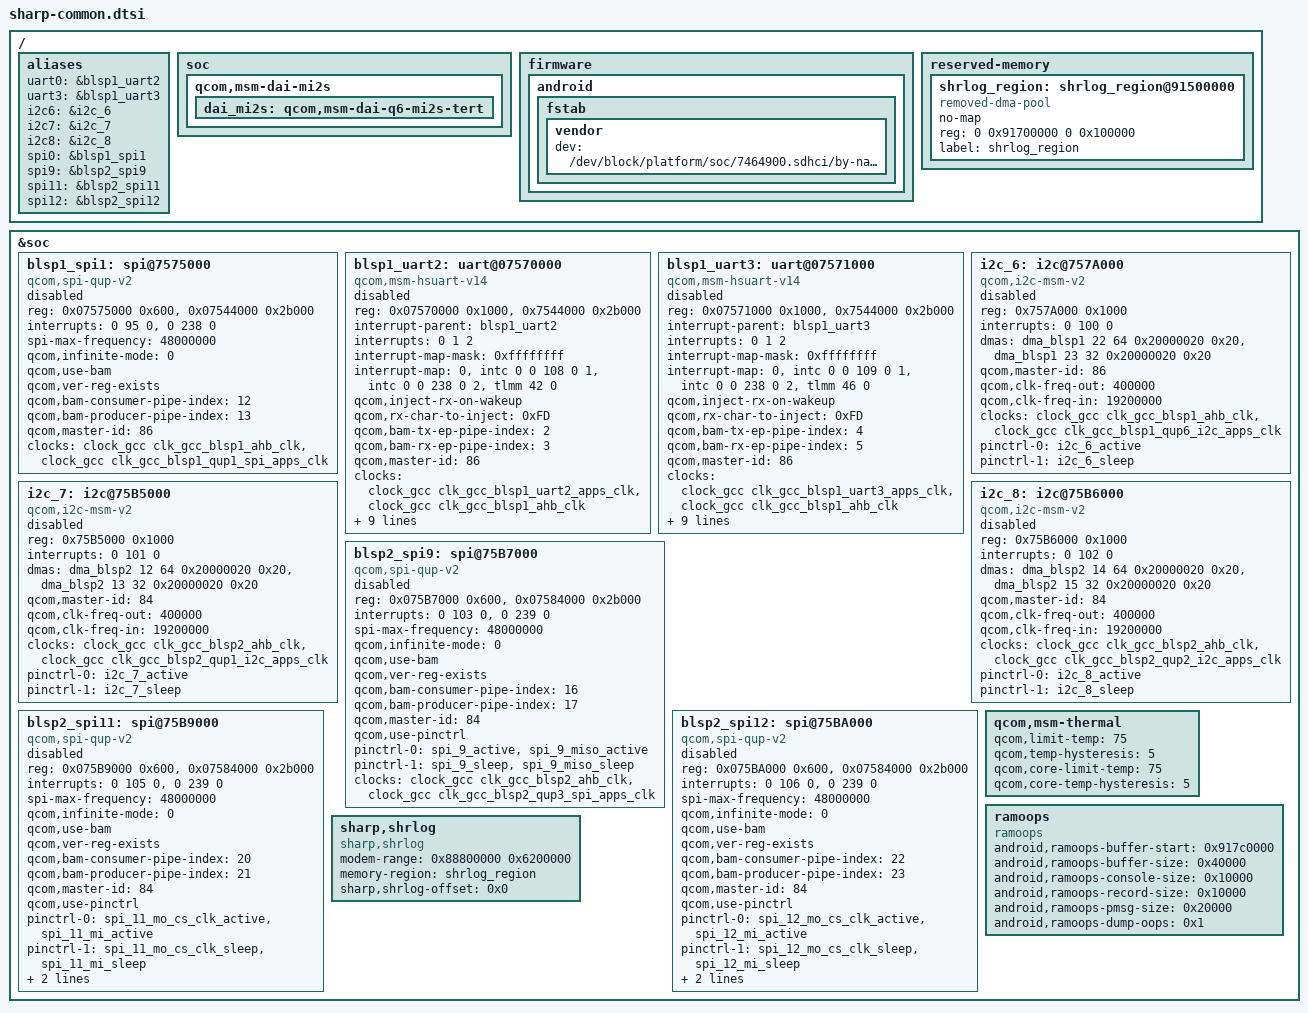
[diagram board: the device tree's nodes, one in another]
/* Copyright (c) 2015, The Linux Foundation. All rights reserved.
 *
 * This program is free software; you can redistribute it and/or modify
 * it under the terms of the GNU General Public License version 2 and
 * only version 2 as published by the Free Software Foundation.
 *
 * This program is distributed in the hope that it will be useful,
 * but WITHOUT ANY WARRANTY; without even the implied warranty of
 * MERCHANTABILITY or FITNESS FOR A PARTICULAR PURPOSE.  See the
 * GNU General Public License for more details.
 */

/*****************************************/
/*  Add SHARP include                    */
/*****************************************/
#include "sharp-pinctrl.dtsi"
#include "sharp-common-pm8996.dtsi"
#include "sharp-common-pmi8994.dtsi"
#include "sharp-common-sdcc.dtsi"

/*----------------------------------------*/
/* Qualcomm settings.                     */
/*----------------------------------------*/
/ {
	aliases {
		uart0 = &blsp1_uart2;
		uart3 = &blsp1_uart3;

		i2c6 = &i2c_6;
		i2c7 = &i2c_7;
		i2c8 = &i2c_8;

		spi0 = &blsp1_spi1;
		spi9 = &blsp2_spi9;
		spi11 = &blsp2_spi11;
		spi12 = &blsp2_spi12;
	};

	soc {
		/delete-node/ i2c@75b5000;
		/delete-node/ i2c@75b6000;
		/delete-node/ i2c@75ba000;
		/delete-node/ spi@7575000;
		/delete-node/ uart@07570000;
		/delete-node/ serial@07570000;
		/delete-node/ serial@075b0000;

		qcom,msm-dai-mi2s {
			dai_mi2s: qcom,msm-dai-q6-mi2s-tert {
				/delete-property/ pinctrl-names;
				/delete-property/ pinctrl-0;
				/delete-property/ pinctrl-1;
			};
		};
	};

	firmware: firmware {
		android {
			fstab {
				vendor {
					dev = "/dev/block/platform/soc/7464900.sdhci/by-name/systemex";
				 };
			};
		};
	};

	/*----------------------------------------------*/
	/* shrlog                                       */
	/*----------------------------------------------*/
	reserved-memory {
		shrlog_region: shrlog_region@91500000 {
			compatible = "removed-dma-pool";
			no-map;
			reg = <0 0x91700000 0 0x100000>;
			label = "shrlog_region";
		};
	};
};

/*----------------------------------------*/
/* Add SHARP settings.                    */
/*----------------------------------------*/
&soc {
	/*---------------------*/
	/* BLSP1 QUP0(BLSP#1)  */
	/*---------------------*/
	blsp1_spi1: spi@7575000 {
		compatible = "qcom,spi-qup-v2";
		#address-cells = <1>;
		#size-cells = <0>;
		reg-names = "spi_physical", "spi_bam_physical";
		reg = <0x07575000 0x600>,
		      <0x07544000 0x2b000>;
		interrupt-names = "spi_irq", "spi_bam_irq";
		interrupts = <0 95 0>, <0 238 0>;
		spi-max-frequency = <48000000>;

		qcom,infinite-mode = <0>;
		qcom,use-bam;
		qcom,ver-reg-exists;
		qcom,bam-consumer-pipe-index = <12>;
		qcom,bam-producer-pipe-index = <13>;
		qcom,master-id = <86>;

		clock-names = "iface_clk", "core_clk";
		clocks = <&clock_gcc clk_gcc_blsp1_ahb_clk>,
			 <&clock_gcc clk_gcc_blsp1_qup1_spi_apps_clk>;
		status = "disabled";
	};

	/*---------------------*/
	/* BLSP1 UART1(BLSP#2) */
	/*---------------------*/
	blsp1_uart2: uart@07570000 {
		compatible = "qcom,msm-hsuart-v14";
		reg = <0x07570000 0x1000>,
		    <0x7544000 0x2b000>;
		reg-names = "core_mem", "bam_mem";
		interrupt-names = "core_irq", "bam_irq", "wakeup_irq";
		#address-cells = <0>;
		interrupt-parent = <&blsp1_uart2>;
		interrupts = <0 1 2>;
		#interrupt-cells = <1>;
		interrupt-map-mask = <0xffffffff>;
		interrupt-map = <0 &intc 0 0 108 0
			    1 &intc 0 0 238 0
			    2 &tlmm 42 0>;

		qcom,inject-rx-on-wakeup;
		qcom,rx-char-to-inject = <0xFD>;

		qcom,bam-tx-ep-pipe-index = <2>;
		qcom,bam-rx-ep-pipe-index = <3>;
		qcom,master-id = <86>;
		clock-names = "core_clk", "iface_clk";
		clocks = <&clock_gcc clk_gcc_blsp1_uart2_apps_clk>,
		    <&clock_gcc clk_gcc_blsp1_ahb_clk>;
		pinctrl-names = "sleep", "default";
// Bluetooth Driver Mod-S
//		pinctrl-0 = <&blsp1_uart2_sleep>;
//		pinctrl-1 = <&blsp1_uart2_active>;
		pinctrl-0 = <&blsp1_uart2_sleep &blsp1_uart2_rts_sleep>;
		pinctrl-1 = <&blsp1_uart2_active &blsp1_uart2_rts_active>;
// Bluetooth Driver Mod-E

		qcom,msm-bus,name = "buart2";
		qcom,msm-bus,num-cases = <2>;
		qcom,msm-bus,num-paths = <1>;
		qcom,msm-bus,vectors-KBps =
			    <86 512 0 0>,
			    <86 512 500 800>;
		status = "disabled";
	};

	/*---------------------*/
	/* BLSP1 UART2(BLSP#3) */
	/*---------------------*/
	blsp1_uart3: uart@07571000 {
		compatible = "qcom,msm-hsuart-v14";
		reg = <0x07571000 0x1000>,
		    <0x7544000 0x2b000>;
		reg-names = "core_mem", "bam_mem";
		interrupt-names = "core_irq", "bam_irq", "wakeup_irq";
		#address-cells = <0>;
		interrupt-parent = <&blsp1_uart3>;
		interrupts = <0 1 2>;
		#interrupt-cells = <1>;
		interrupt-map-mask = <0xffffffff>;
		interrupt-map = <0 &intc 0 0 109 0
			    1 &intc 0 0 238 0
			    2 &tlmm 46 0>;

		qcom,inject-rx-on-wakeup;
		qcom,rx-char-to-inject = <0xFD>;

		qcom,bam-tx-ep-pipe-index = <4>;
		qcom,bam-rx-ep-pipe-index = <5>;
		qcom,master-id = <86>;
		clock-names = "core_clk", "iface_clk";
		clocks = <&clock_gcc clk_gcc_blsp1_uart3_apps_clk>,
		    <&clock_gcc clk_gcc_blsp1_ahb_clk>;
		pinctrl-names = "sleep", "default";
		pinctrl-0 = <&blsp1_uart3_sleep_tx_rx &blsp1_uart3_sleep_cts_ref>;
		pinctrl-1 = <&blsp1_uart3_active_tx_rx &blsp1_uart3_active_cts_ref>;

		qcom,msm-bus,name = "buart3";
		qcom,msm-bus,num-cases = <2>;
		qcom,msm-bus,num-paths = <1>;
		qcom,msm-bus,vectors-KBps =
			    <86 512 0 0>,
			    <86 512 500 800>;
		status = "disabled";
	};

	/*---------------------*/
	/* BLSP#4              */
	/*---------------------*/

	/*---------------------*/
	/* BLSP#5              */
	/*---------------------*/

	/*---------------------*/
	/* BLSP1 QUP5(BLSP#6)  */
	/*---------------------*/
	i2c_6: i2c@757A000 {
		compatible = "qcom,i2c-msm-v2";
		#address-cells = <1>;
		#size-cells = <0>;
		reg-names = "qup_phys_addr";
		reg = <0x757A000 0x1000>;
		interrupt-names = "qup_irq";
		interrupts = <0 100 0>;
		dmas = <&dma_blsp1 22 64 0x20000020 0x20>,
			<&dma_blsp1 23 32 0x20000020 0x20>;
		dma-names = "tx", "rx";
		qcom,master-id = <86>;
		qcom,clk-freq-out = <400000>;
		qcom,clk-freq-in  = <19200000>;
		clock-names = "iface_clk", "core_clk";
		clocks = <&clock_gcc clk_gcc_blsp1_ahb_clk>,
			 <&clock_gcc clk_gcc_blsp1_qup6_i2c_apps_clk>;
		pinctrl-names = "i2c_active", "i2c_sleep";
		pinctrl-0 = <&i2c_6_active>;
		pinctrl-1 = <&i2c_6_sleep>;
		status = "disabled";
	};

	/*---------------------*/
	/* BLSP2 QUP0(BLSP#7)  */
	/*---------------------*/
	i2c_7: i2c@75B5000 {
		compatible = "qcom,i2c-msm-v2";
		#address-cells = <1>;
		#size-cells = <0>;
		reg-names = "qup_phys_addr";
		reg = <0x75B5000 0x1000>;
		interrupt-names = "qup_irq";
		interrupts = <0 101 0>;
		dmas = <&dma_blsp2 12 64 0x20000020 0x20>,
			<&dma_blsp2 13 32 0x20000020 0x20>;
		dma-names = "tx", "rx";
		qcom,master-id = <84>;
		qcom,clk-freq-out = <400000>;
		qcom,clk-freq-in  = <19200000>;
		clock-names = "iface_clk", "core_clk";
		clocks = <&clock_gcc clk_gcc_blsp2_ahb_clk>,
			 <&clock_gcc clk_gcc_blsp2_qup1_i2c_apps_clk>;
		pinctrl-names = "i2c_active", "i2c_sleep";
		pinctrl-0 = <&i2c_7_active>;
		pinctrl-1 = <&i2c_7_sleep>;
		status = "disabled";
	};

	/*---------------------*/
	/* BLSP2 QUP1(BLSP#8)  */
	/*---------------------*/
	i2c_8: i2c@75B6000 {
		compatible = "qcom,i2c-msm-v2";
		#address-cells = <1>;
		#size-cells = <0>;
		reg-names = "qup_phys_addr";
		reg = <0x75B6000 0x1000>;
		interrupt-names = "qup_irq";
		interrupts = <0 102 0>;
		dmas = <&dma_blsp2 14 64 0x20000020 0x20>,
			<&dma_blsp2 15 32 0x20000020 0x20>;
		dma-names = "tx", "rx";
		qcom,master-id = <84>;
		qcom,clk-freq-out = <400000>;
		qcom,clk-freq-in  = <19200000>;
		clock-names = "iface_clk", "core_clk";
		clocks = <&clock_gcc clk_gcc_blsp2_ahb_clk>,
			 <&clock_gcc clk_gcc_blsp2_qup2_i2c_apps_clk>;
		pinctrl-names = "i2c_active", "i2c_sleep";
		pinctrl-0 = <&i2c_8_active>;
		pinctrl-1 = <&i2c_8_sleep>;
		status = "disabled";
	};

	/*---------------------*/
	/* BLSP2 QUP2(BLSP#9)  */
	/*---------------------*/
	blsp2_spi9: spi@75B7000 {
		compatible = "qcom,spi-qup-v2";
		#address-cells = <1>;
		#size-cells = <0>;
		reg-names = "spi_physical", "spi_bam_physical";
		reg = <0x075B7000 0x600>,
		      <0x07584000 0x2b000>;
		interrupt-names = "spi_irq", "spi_bam_irq";
		interrupts = <0 103 0>, <0 239 0>;
		spi-max-frequency = <48000000>;

		qcom,infinite-mode = <0>;
		qcom,use-bam;
		qcom,ver-reg-exists;
		qcom,bam-consumer-pipe-index = <16>;
		qcom,bam-producer-pipe-index = <17>;
		qcom,master-id = <84>;
		qcom,use-pinctrl;
		pinctrl-names = "spi_default", "spi_sleep";
		pinctrl-0 = <&spi_9_active &spi_9_miso_active>;
		pinctrl-1 = <&spi_9_sleep &spi_9_miso_sleep>;

		clock-names = "iface_clk", "core_clk";

		clocks = <&clock_gcc clk_gcc_blsp2_ahb_clk>,
			 <&clock_gcc clk_gcc_blsp2_qup3_spi_apps_clk>;
		status = "disabled";
	};

	/*---------------------*/
	/* BLSP#10             */
	/*---------------------*/

	/*---------------------*/
	/* BLSP2 QUP4(BLSP#11) */
	/*---------------------*/
	blsp2_spi11: spi@75B9000 {
		compatible = "qcom,spi-qup-v2";
		#address-cells = <1>;
		#size-cells = <0>;
		reg-names = "spi_physical", "spi_bam_physical";
		reg = <0x075B9000 0x600>,
		      <0x07584000 0x2b000>;
		interrupt-names = "spi_irq", "spi_bam_irq";
		interrupts = <0 105 0>, <0 239 0>;
		spi-max-frequency = <48000000>;

		qcom,infinite-mode = <0>;
		qcom,use-bam;
		qcom,ver-reg-exists;
		qcom,bam-consumer-pipe-index = <20>;
		qcom,bam-producer-pipe-index = <21>;
		qcom,master-id = <84>;
		qcom,use-pinctrl;
		pinctrl-names = "spi_default", "spi_sleep";
		pinctrl-0 = <&spi_11_mo_cs_clk_active &spi_11_mi_active>;
		pinctrl-1 = <&spi_11_mo_cs_clk_sleep &spi_11_mi_sleep>;

		clock-names = "iface_clk", "core_clk";

		clocks = <&clock_gcc clk_gcc_blsp2_ahb_clk>,
			 <&clock_gcc clk_gcc_blsp2_qup5_spi_apps_clk>;
		status = "disabled";
	};

	/*---------------------*/
	/* BLSP2 QUP5(BLSP#12) */
	/*---------------------*/
	blsp2_spi12: spi@75BA000 {
		compatible = "qcom,spi-qup-v2";
		#address-cells = <1>;
		#size-cells = <0>;
		reg-names = "spi_physical", "spi_bam_physical";
		reg = <0x075BA000 0x600>,
		      <0x07584000 0x2b000>;
		interrupt-names = "spi_irq", "spi_bam_irq";
		interrupts = <0 106 0>, <0 239 0>;
		spi-max-frequency = <48000000>;

		qcom,infinite-mode = <0>;
		qcom,use-bam;
		qcom,ver-reg-exists;
		qcom,bam-consumer-pipe-index = <22>;
		qcom,bam-producer-pipe-index = <23>;
		qcom,master-id = <84>;
		qcom,use-pinctrl;
		pinctrl-names = "spi_default", "spi_sleep";
		pinctrl-0 = <&spi_12_mo_cs_clk_active &spi_12_mi_active>;
		pinctrl-1 = <&spi_12_mo_cs_clk_sleep &spi_12_mi_sleep>;

		clock-names = "iface_clk", "core_clk";

		clocks = <&clock_gcc clk_gcc_blsp2_ahb_clk>,
			 <&clock_gcc clk_gcc_blsp2_qup6_spi_apps_clk>;
		status = "disabled";
	};

    /*--------------------------------------------------*/
    /* msm_thermal cpu_clock/cpu restriction thresholds */
    /*--------------------------------------------------*/
    qcom,msm-thermal {
        qcom,limit-temp = <75>;
        qcom,temp-hysteresis = <5>;
        qcom,core-limit-temp = <75>;
        qcom,core-temp-hysteresis = <5>;
    };

	/*----------------------------------------------*/
	/* ramoops(shrlog)                              */
	/*----------------------------------------------*/
	ramoops {
		compatible = "ramoops";
		status = "okay";
		android,ramoops-buffer-start = <0x917c0000>;
		android,ramoops-buffer-size =  <0x40000>;
		android,ramoops-console-size = <0x10000>;
		android,ramoops-record-size = <0x10000>;
		android,ramoops-pmsg-size = <0x20000>;
		android,ramoops-dump-oops = <0x1>;
	};

	/*----------------------------------------------*/
	/* shrlog                                       */
	/*----------------------------------------------*/
	sharp,shrlog {
		compatible = "sharp,shrlog";
		modem-range = <0x88800000 0x6200000>;
		memory-region = <&shrlog_region>;
		sharp,shrlog-offset = <0x0>;
		/* sharp,shrlog-smem; */
		/* sharp,shrlog-offset = <0x1fefe0>; */
	};


};

#include "msm8996-camera-sensor-23M-5M.dtsi"
